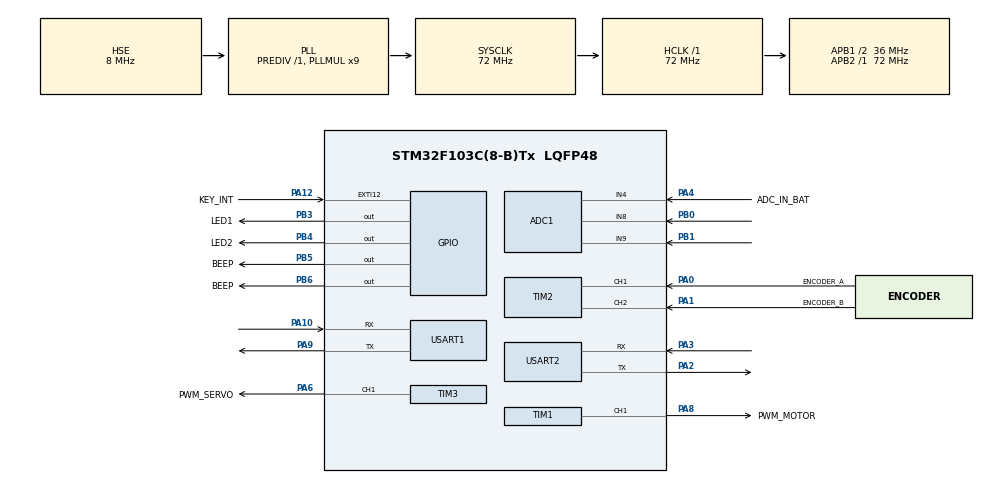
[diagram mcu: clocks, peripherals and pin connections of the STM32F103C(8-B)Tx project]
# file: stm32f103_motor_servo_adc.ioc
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ADC1.Channel-0\#ChannelRegularConversion=ADC_CHANNEL_4
ADC1.Channel-1\#ChannelRegularConversion=ADC_CHANNEL_8
ADC1.Channel-2\#ChannelRegularConversion=ADC_CHANNEL_9
ADC1.ContinuousConvMode=ENABLE
ADC1.DiscontinuousConvMode=DISABLE
ADC1.NbrOfConversion=3
ADC1.NbrOfConversionFlag=1
ADC1.Rank-0\#ChannelRegularConversion=1
ADC1.Rank-1\#ChannelRegularConversion=2
ADC1.Rank-2\#ChannelRegularConversion=3
ADC1.SamplingTime-0\#ChannelRegularConversion=ADC_SAMPLETIME_239CYCLES_5
ADC1.SamplingTime-1\#ChannelRegularConversion=ADC_SAMPLETIME_239CYCLES_5
ADC1.SamplingTime-2\#ChannelRegularConversion=ADC_SAMPLETIME_239CYCLES_5
ADC1.master=1
Dma.ADC1.0.Direction=DMA_PERIPH_TO_MEMORY
Dma.ADC1.0.Instance=DMA1_Channel1
Dma.ADC1.0.MemDataAlignment=DMA_MDATAALIGN_HALFWORD
Dma.ADC1.0.MemInc=DMA_MINC_ENABLE
Dma.ADC1.0.Mode=DMA_CIRCULAR
Dma.ADC1.0.PeriphDataAlignment=DMA_PDATAALIGN_HALFWORD
Dma.ADC1.0.PeriphInc=DMA_PINC_DISABLE
Dma.ADC1.0.Priority=DMA_PRIORITY_LOW
Dma.Request0=ADC1
Dma.Request1=USART2_RX
Dma.USART2_RX.1.Direction=DMA_PERIPH_TO_MEMORY
Dma.USART2_RX.1.Instance=DMA1_Channel6
Dma.USART2_RX.1.MemDataAlignment=DMA_MDATAALIGN_BYTE
Dma.USART2_RX.1.MemInc=DMA_MINC_ENABLE
Dma.USART2_RX.1.Mode=DMA_NORMAL
Dma.USART2_RX.1.PeriphDataAlignment=DMA_PDATAALIGN_BYTE
Dma.USART2_RX.1.PeriphInc=DMA_PINC_DISABLE
Dma.USART2_RX.1.Priority=DMA_PRIORITY_LOW
IWDG.Prescaler=IWDG_PRESCALER_256
IWDG.Reload=250
Mcu.Family=STM32F1
Mcu.Name=STM32F103C(8-B)Tx
Mcu.Package=LQFP48
NVIC.DMA1_Channel1_IRQn=true\:0\:0\:false\:false\:true\:false\:true\:true
NVIC.DMA1_Channel6_IRQn=true\:0\:0\:false\:false\:true\:false\:true\:true
NVIC.EXTI15_10_IRQn=true\:0\:0\:false\:false\:true\:true\:true\:true
NVIC.PriorityGroup=NVIC_PRIORITYGROUP_4
NVIC.USART1_IRQn=true\:0\:0\:false\:false\:true\:true\:true\:true
NVIC.USART2_IRQn=true\:0\:0\:false\:false\:true\:true\:true\:true
PA0-WKUP.GPIO_Label=ENCODER_A
PA0-WKUP.Signal=S_TIM2_CH1_ETR
PA1.GPIO_Label=ENCODER_B
PA1.Signal=S_TIM2_CH2
PA10.Mode=Asynchronous
PA10.Signal=USART1_RX
PA12.GPIO_Label=KEY_INT
PA12.GPIO_ModeDefaultEXTI=GPIO_MODE_IT_FALLING
PA12.GPIO_PuPd=GPIO_PULLUP
PA12.Signal=GPXTI12
PA13.Mode=Serial_Wire
PA13.Signal=SYS_JTMS-SWDIO
PA14.Mode=Serial_Wire
PA14.Signal=SYS_JTCK-SWCLK
PA2.Mode=Asynchronous
PA2.Signal=USART2_TX
PA3.Mode=Asynchronous
PA3.Signal=USART2_RX
PA4.GPIO_Label=ADC_IN_BAT
PA4.Signal=ADCx_IN4
PA6.GPIO_Label=PWM_SERVO
PA6.Signal=S_TIM3_CH1
PA8.GPIO_Label=PWM_MOTOR
PA8.Signal=S_TIM1_CH1
PA9.Mode=Asynchronous
PA9.Signal=USART1_TX
PB0.Signal=ADCx_IN8
PB1.Signal=ADCx_IN9
PB3.GPIO_Label=LED1
PB3.GPIO_Speed=GPIO_SPEED_FREQ_HIGH
PB3.Signal=GPIO_Output
PB4.GPIO_Label=LED2
PB4.GPIO_Speed=GPIO_SPEED_FREQ_HIGH
PB4.Signal=GPIO_Output
PB5.GPIO_Label=BEEP
PB5.GPIO_Speed=GPIO_SPEED_FREQ_HIGH
PB5.Signal=GPIO_Output
PB6.GPIO_Label=BEEP
PB6.GPIO_Speed=GPIO_SPEED_FREQ_HIGH
PB6.Signal=GPIO_Output
PC14-OSC32_IN.Mode=LSE-External-Oscillator
PC14-OSC32_IN.Signal=RCC_OSC32_IN
PC15-OSC32_OUT.Mode=LSE-External-Oscillator
PC15-OSC32_OUT.Signal=RCC_OSC32_OUT
PD0-OSC_IN.Mode=HSE-External-Oscillator
PD0-OSC_IN.Signal=RCC_OSC_IN
PD1-OSC_OUT.Mode=HSE-External-Oscillator
PD1-OSC_OUT.Signal=RCC_OSC_OUT
ProjectManager.HeapSize=0x200
ProjectManager.StackSize=0x800
ProjectManager.TargetToolchain=MDK-ARM V5.32
RCC.ADCPresc=RCC_ADCPCLK2_DIV6
RCC.AHBFreq_Value=72000000
RCC.APB1CLKDivider=RCC_HCLK_DIV2
RCC.APB1Freq_Value=36000000
RCC.APB1TimFreq_Value=72000000
RCC.APB2Freq_Value=72000000
RCC.APB2TimFreq_Value=72000000
RCC.HCLKFreq_Value=72000000
RCC.PLLMUL=RCC_PLL_MUL9
RCC.PLLSourceVirtual=RCC_PLLSOURCE_HSE
RCC.SYSCLKFreq_VALUE=72000000
RCC.SYSCLKSource=RCC_SYSCLKSOURCE_PLLCLK
RCC.USBFreq_Value=72000000
SH.ADCx_IN4.0=ADC1_IN4,IN4
SH.ADCx_IN8.0=ADC1_IN8,IN8
SH.ADCx_IN9.0=ADC1_IN9,IN9
SH.S_TIM1_CH1.0=TIM1_CH1,PWM Generation1 CH1
SH.S_TIM2_CH1_ETR.0=TIM2_CH1,Encoder_Interface
SH.S_TIM2_CH2.0=TIM2_CH2,Encoder_Interface
SH.S_TIM3_CH1.0=TIM3_CH1,PWM Generation1 CH1
TIM1.AutoReloadPreload=TIM_AUTORELOAD_PRELOAD_ENABLE
TIM1.Channel-PWM\ Generation1\ CH1=TIM_CHANNEL_1
TIM1.Period=999
TIM1.Prescaler=71
TIM2.EncoderMode=TIM_ENCODERMODE_TI12
TIM3.AutoReloadPreload=TIM_AUTORELOAD_PRELOAD_ENABLE
TIM3.Channel-PWM\ Generation1\ CH1=TIM_CHANNEL_1
TIM3.Period=19999
TIM3.Prescaler=71
TIM3.Pulse-PWM\ Generation1\ CH1=1500
USART1.VirtualMode=VM_ASYNC
USART2.VirtualMode=VM_ASYNC
VP_IWDG_VS_IWDG.Mode=IWDG_Activate
VP_TIM1_VS_ClockSourceINT.Mode=Internal
board=custom

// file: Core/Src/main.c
/* USER CODE BEGIN Header */
/**
  ******************************************************************************
  * @file           : main.c
  * @brief          : Main program body
  ******************************************************************************
  * @attention
  *
  * Copyright (c) 2026 STMicroelectronics.
  * All rights reserved.
  *
  * This software is licensed under terms that can be found in the LICENSE file
  * in the root directory of this software component.
  * If no LICENSE file comes with this software, it is provided AS-IS.
  *
  ******************************************************************************
  */
/* USER CODE END Header */
#include "main.h"
#include "adc.h"
#include "dma.h"
#include "iwdg.h"
#include "tim.h"
#include "usart.h"
#include "gpio.h"

/* USER CODE BEGIN Includes */
#include <stdio.h>   /* fputc 里的 FILE *f 需要 */
#include "app_main.h"

/* USER CODE END Includes */

void SystemClock_Config(void);

/* USER CODE BEGIN 0 */

int fputc(int ch, FILE *f)
{
    HAL_UART_Transmit(&huart1, (uint8_t *)&ch,1,0xFFFF);
    return ch;
}

/* USER CODE END 0 */

int main(void)
{

  /* USER CODE BEGIN 1 */
  /* 释放 PB3/PB4 的 JTAG 功能，改作普通 GPIO（电机方向脚 AIN1/AIN2 用）。
     注意：只关 JTAG、保留 SWD(PA13/PA14)，否则无法再调试下载。 */
  __HAL_RCC_AFIO_CLK_ENABLE();
  uint32_t mapr = AFIO->MAPR;
  mapr &= ~AFIO_MAPR_SWJ_CFG;   /* 清除 SWJ_CFG[26:24] */
  mapr |=  0x02000000U;         /* 010 = 关闭 JTAG，保留 SWD */
  AFIO->MAPR = mapr;
  /* USER CODE END 1 */

  /* MCU Configuration--------------------------------------------------------*/

  /* Reset of all peripherals, Initializes the Flash interface and the Systick. */
  HAL_Init();

  /* Configure the system clock */
  SystemClock_Config();

  /* Initialize all configured peripherals */
  MX_GPIO_Init();
  MX_DMA_Init();
  MX_ADC1_Init();
  MX_TIM1_Init();
  MX_TIM2_Init();
  MX_TIM3_Init();
  MX_USART1_UART_Init();
  MX_USART2_UART_Init();
  MX_IWDG_Init();
  /* USER CODE BEGIN 2 */
  app_main();   /* 启动应用主循环：Modbus 从站 + 电机控制。必须在 USART2 初始化之后调用 */

  /* USER CODE END 2 */

  /* Infinite loop */
  while (1)
  {

  }
}

void SystemClock_Config(void)
{
  RCC_OscInitTypeDef RCC_OscInitStruct = {0};
  RCC_ClkInitTypeDef RCC_ClkInitStruct = {0};
  RCC_PeriphCLKInitTypeDef PeriphClkInit = {0};

  /** Initializes the RCC Oscillators according to the specified parameters
  * in the RCC_OscInitTypeDef structure.
  */
  RCC_OscInitStruct.OscillatorType = RCC_OSCILLATORTYPE_LSI|RCC_OSCILLATORTYPE_HSE;
  RCC_OscInitStruct.HSEState = RCC_HSE_ON;
  RCC_OscInitStruct.HSEPredivValue = RCC_HSE_PREDIV_DIV1;
  RCC_OscInitStruct.HSIState = RCC_HSI_ON;
  RCC_OscInitStruct.LSIState = RCC_LSI_ON;
  RCC_OscInitStruct.PLL.PLLState = RCC_PLL_ON;
  RCC_OscInitStruct.PLL.PLLSource = RCC_PLLSOURCE_HSE;
  RCC_OscInitStruct.PLL.PLLMUL = RCC_PLL_MUL9;
  if (HAL_RCC_OscConfig(&RCC_OscInitStruct) != HAL_OK)
  {
    Error_Handler();
  }

  /** Initializes the CPU, AHB and APB buses clocks
  */
  RCC_ClkInitStruct.ClockType = RCC_CLOCKTYPE_HCLK|RCC_CLOCKTYPE_SYSCLK
                              |RCC_CLOCKTYPE_PCLK1|RCC_CLOCKTYPE_PCLK2;
  RCC_ClkInitStruct.SYSCLKSource = RCC_SYSCLKSOURCE_PLLCLK;
  RCC_ClkInitStruct.AHBCLKDivider = RCC_SYSCLK_DIV1;
  RCC_ClkInitStruct.APB1CLKDivider = RCC_HCLK_DIV2;
  RCC_ClkInitStruct.APB2CLKDivider = RCC_HCLK_DIV1;

  if (HAL_RCC_ClockConfig(&RCC_ClkInitStruct, FLASH_LATENCY_2) != HAL_OK)
  {
    Error_Handler();
  }
  PeriphClkInit.PeriphClockSelection = RCC_PERIPHCLK_ADC;
  PeriphClkInit.AdcClockSelection = RCC_ADCPCLK2_DIV6;
  if (HAL_RCCEx_PeriphCLKConfig(&PeriphClkInit) != HAL_OK)
  {
    Error_Handler();
  }
}

void Error_Handler(void)
{
  __disable_irq();
  while (1)
  {
  }
}
